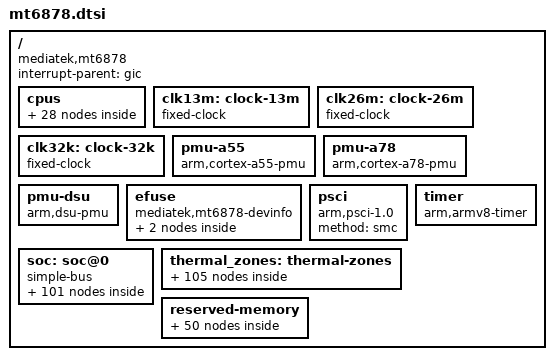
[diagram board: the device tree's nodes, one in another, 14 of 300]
// SPDX-License-Identifier: GPL-2.0 OR BSD-3-Clause
/*
 * MediaTek MT6878 SoC device tree source
 *
 * Copyright (c) 2025, Igor Belwon <igor.belwon@mentallysanemainliners.org>
 */

#include <dt-bindings/clock/mediatek,mt6878-clock.h>
#include <dt-bindings/interrupt-controller/arm-gic.h>
#include <dt-bindings/interrupt-controller/irq.h>
#include <dt-bindings/phy/phy.h>
#include <dt-bindings/power/mediatek,mt6878-power.h>
#include <dt-bindings/reset/ti-syscon.h>
#include <dt-bindings/thermal/mediatek,lvts-thermal.h>
#include <dt-bindings/thermal/thermal.h>
#include "mt6878-pinfunc.h"

/ {
	compatible = "mediatek,mt6878";
	#address-cells = <2>;
	#size-cells = <1>;

	interrupt-parent = <&gic>;

	cpus {
		#address-cells = <1>;
		#size-cells = <0>;

		cpu-map {
			cluster0 {
				core0 {
					cpu = <&cpu0>;
				};
				core1 {
					cpu = <&cpu1>;
				};
				core2 {
					cpu = <&cpu2>;
				};
				core3 {
					cpu = <&cpu3>;
				};
			};

			cluster1 {
				core0 {
					cpu = <&cpu4>;
				};
				core1 {
					cpu = <&cpu5>;
				};
				core2 {
					cpu = <&cpu6>;
				};
				core3 {
					cpu = <&cpu7>;
				};
			};
		};

		cpu0: cpu@0 {
			device_type = "cpu";
			compatible = "arm,cortex-a55";
			reg = <0x0>;
			performance-domains = <&performance 0>;
			enable-method = "psci";
			cpu-idle-states = <&cpuoff_l &clusteroff_l &mcusysoff_l
						&system_vcore &s2idle>;
			capacity-dmips-mhz  = <267>;
			#cooling-cells = <2>;
		};

		cpu1: cpu@1 {
			device_type = "cpu";
			compatible = "arm,cortex-a55";
			reg = <0x100>;
			performance-domains = <&performance 0>;
			enable-method = "psci";
			cpu-idle-states = <&cpuoff_l &clusteroff_l &mcusysoff_l
						&system_vcore &s2idle>;
			capacity-dmips-mhz  = <267>;
			#cooling-cells = <2>;
		};

		cpu2: cpu@2 {
			device_type = "cpu";
			compatible = "arm,cortex-a55";
			reg = <0x200>;
			performance-domains = <&performance 0>;
			enable-method = "psci";
			cpu-idle-states = <&cpuoff_l &clusteroff_l &mcusysoff_l
						&system_vcore &s2idle>;
			capacity-dmips-mhz  = <267>;
			#cooling-cells = <2>;
		};

		cpu3: cpu@3 {
			device_type = "cpu";
			compatible = "arm,cortex-a55";
			reg = <0x300>;
			performance-domains = <&performance 0>;
			enable-method = "psci";
			cpu-idle-states = <&cpuoff_l &clusteroff_l &mcusysoff_l
						&system_vcore &s2idle>;
			capacity-dmips-mhz  = <267>;
			#cooling-cells = <2>;
		};

		cpu4: cpu@100 {
			device_type = "cpu";
			compatible = "arm,cortex-a78";
			reg = <0x400>;
			performance-domains = <&performance 1>;
			enable-method = "psci";
			cpu-idle-states = <&cpuoff_b &clusteroff_b &mcusysoff_b
						&system_vcore &s2idle>;
			capacity-dmips-mhz  = <1024>;
			#cooling-cells = <2>;
		};

		cpu5: cpu@101 {
			device_type = "cpu";
			compatible = "arm,cortex-a78";
			reg = <0x500>;
			performance-domains = <&performance 1>;
			enable-method = "psci";
			cpu-idle-states = <&cpuoff_b &clusteroff_b &mcusysoff_b
						&system_vcore &s2idle>;
			capacity-dmips-mhz  = <1024>;
			#cooling-cells = <2>;
		};

		cpu6: cpu@102 {
			device_type = "cpu";
			compatible = "arm,cortex-a78";
			reg = <0x600>;
			performance-domains = <&performance 1>;
			enable-method = "psci";
			cpu-idle-states = <&cpuoff_b &clusteroff_b &mcusysoff_b
						&system_vcore &s2idle>;
			capacity-dmips-mhz  = <1024>;
			#cooling-cells = <2>;
		};

		cpu7: cpu@103 {
			device_type = "cpu";
			compatible = "arm,cortex-a78";
			reg = <0x700>;
			performance-domains = <&performance 1>;
			enable-method = "psci";
			cpu-idle-states = <&cpuoff_b &clusteroff_b &mcusysoff_b
						&system_vcore &s2idle>;
			capacity-dmips-mhz  = <1024>;
			#cooling-cells = <2>;
		};

		idle-states {
			entry-method = "arm,psci";

			cpuoff_l: cpuoff-l {
				compatible = "arm,idle-state";
				arm,psci-suspend-param = <0x00010000>;
				local-timer-stop;
				entry-latency-us = <25>;
				exit-latency-us = <57>;
				min-residency-us = <5700>;
			};

			cpuoff_b: cpuoff-b {
				compatible = "arm,idle-state";
				arm,psci-suspend-param = <0x00010000>;
				local-timer-stop;
				entry-latency-us = <35>;
				exit-latency-us = <82>;
				min-residency-us = <1890>;
			};

			clusteroff_l: clusteroff-l {
				compatible = "arm,idle-state";
				arm,psci-suspend-param = <0x01010001>;
				local-timer-stop;
				entry-latency-us = <57>;
				exit-latency-us = <134>;
				min-residency-us = <5700>;
			};

			clusteroff_b: clusteroff-b {
				compatible = "arm,idle-state";
				arm,psci-suspend-param = <0x01010001>;
				local-timer-stop;
				entry-latency-us = <50>;
				exit-latency-us = <144>;
				min-residency-us = <2460>;
			};

			mcusysoff_l: mcusysoff-l {
				compatible = "arm,idle-state";
				arm,psci-suspend-param = <0x02010007>;
				local-timer-stop;
				entry-latency-us = <863>;
				exit-latency-us = <1237>;
				min-residency-us = <5700>;
			};

			mcusysoff_b: mcusysoff-b {
				compatible = "arm,idle-state";
				arm,psci-suspend-param = <0x02010007>;
				local-timer-stop;
				entry-latency-us = <648>;
				exit-latency-us = <1172>;
				min-residency-us = <4570>;
			};

			system_vcore: system-vcore {
				compatible = "arm,idle-state";
				arm,psci-suspend-param = <0x020100ff>;
				local-timer-stop;
				entry-latency-us = <2400>;
				exit-latency-us = <4800>;
				min-residency-us = <35200>;
			};

			s2idle: s2idle {
				compatible = "arm,idle-state";
				arm,psci-suspend-param = <0x020180ff>;
				local-timer-stop;
				entry-latency-us = <10000>;
				exit-latency-us = <10000>;
				min-residency-us = <4294967295>;
			};
		};
	};

	clk13m: clock-13m {
		compatible = "fixed-clock";
		#clock-cells = <0>;
		clock-frequency = <13000000>;
		clock-output-names = "clk13m";
	};

	clk26m: clock-26m {
		compatible = "fixed-clock";
		#clock-cells = <0>;
		clock-frequency = <26000000>;
		clock-output-names = "clk26m";
	};

	clk32k: clock-32k {
		compatible = "fixed-clock";
		#clock-cells = <0>;
		clock-frequency = <32000>;
		clock-output-names = "clk32k";
	};

	pmu-a55 {
		compatible = "arm,cortex-a55-pmu";
		interrupt-parent = <&gic>;
		interrupts = <GIC_PPI 7 IRQ_TYPE_LEVEL_HIGH &ppi_cluster0>;
	};

	pmu-a78 {
		compatible = "arm,cortex-a78-pmu";
		interrupt-parent = <&gic>;
		interrupts = <GIC_PPI 7 IRQ_TYPE_LEVEL_HIGH &ppi_cluster1>;
	};

	pmu-dsu {
		compatible = "arm,dsu-pmu";
		cpus = <&cpu0>, <&cpu1>, <&cpu2>, <&cpu3>,
		       <&cpu4>, <&cpu5>, <&cpu6>, <&cpu7>;
		interrupts = <GIC_SPI 35 IRQ_TYPE_LEVEL_HIGH 0>;
	};

	/* efuse copy that LK passes in /chosen "atag,devinfo" */
	efuse: efuse {
		compatible = "mediatek,mt6878-devinfo";
		#address-cells = <1>;
		#size-cells = <1>;

		lvts_efuse_data1: lvts-data1@1ac {
			reg = <0x1ac 0x30>;
		};

		lvts_efuse_data2: lvts-data2@140 {
			reg = <0x140 0x14>;
		};
	};

	psci {
		compatible = "arm,psci-1.0";
		method = "smc";
	};

	soc: soc@0 {
		compatible = "simple-bus";
		ranges = <0x0 0x0 0x0 0x20000000>;

		#address-cells = <1>;
		#size-cells = <1>;

		/*
		 * CPU DVFS by the MCUPM firmware that the boot loader starts:
		 * the LUTs (frequencies, EM power) live in its CSRAM, the
		 * voltages are its business. 0x11c0cc: perf state in kHz flag.
		 */
		performance: performance-controller@11bc00 {
			compatible = "mediatek,mt6878-cpufreq-hw";
			reg = <0x0011bc10 0x120>,
			      <0x0011bd30 0x120>,
			      <0x0011c0cc 0x4>;
			#performance-domain-cells = <1>;
		};

		gic: interrupt-controller@c000000 {
			compatible = "arm,gic-v3";
			reg = <0x0c000000 0x40000>,
			      <0x0c040000 0x200000>;

			#interrupt-cells = <4>;
			interrupt-controller;
			interrupts = <GIC_PPI 9 IRQ_TYPE_LEVEL_HIGH 0>;

			ppi-partitions {
				ppi_cluster0: interrupt-partition-0 {
					affinity = <&cpu0 &cpu1 &cpu2 &cpu3>;
				};
				ppi_cluster1: interrupt-partition-1 {
					affinity = <&cpu4 &cpu5 &cpu6 &cpu7>;
				};
			};
		};

		/*
		 * Modem (CCCI). The node name is fixed: the stock LK looks
		 * up "/soc/mddriver" and writes "ccci,modem_info_v2" (where
		 * it left the modem arguments) into it; if LK did not start
		 * the modem it also sets status = "disabled".
		 *
		 * The MD power domain is not described on purpose (see
		 * scpsys): nothing may switch the modem until its driver
		 * owns the whole power sequence.
		 */
		modem: mddriver@d180000 {
			compatible = "mediatek,mt6878-ccci";
			reg = <0x0d180000 0x2000>,
			      <0x10209000 0x1000>,
			      <0x1020a000 0x1000>;
			reg-names = "md", "ccif-ap", "ccif-md";
			interrupts = <GIC_SPI 491 IRQ_TYPE_LEVEL_HIGH 0>,
				     <GIC_SPI 228 IRQ_TYPE_LEVEL_HIGH 0>,
				     <GIC_SPI 229 IRQ_TYPE_LEVEL_HIGH 0>;
			interrupt-names = "wdt", "ccif0", "ccif1";
			clocks = <&infracfg_ao CLK_IFRAO_CCIF_AP>,
				 <&infracfg_ao CLK_IFRAO_CCIF_MD>,
				 <&infracfg_ao CLK_IFRAO_CCIF1_AP>,
				 <&infracfg_ao CLK_IFRAO_CCIF1_MD>,
				 <&infracfg_ao CLK_IFRAO_CCIF4_MD>,
				 <&infracfg_ao CLK_IFRAO_CCIF5_MD>;
			clock-names = "ccif-ap", "ccif-md", "ccif1-ap",
				      "ccif1-md", "ccif4-md", "ccif5-md";
			mediatek,ccif-sram-size = <0x200>;
			status = "disabled";
		};

		topckgen: syscon@10000000 {
			compatible = "mediatek,mt6878-topckgen", "syscon";
			reg = <0x10000000 0x1000>;
			#clock-cells = <1>;

			hw-voter-regmap = <&hwv>;
		};

		infracfg_ao: clock-controller@10001000 {
			compatible = "mediatek,mt6878-infracfg-ao", "syscon";
			reg = <0x10001000 0x1000>;
			#clock-cells = <1>;
		};

		pio: pinctrl {
			compatible = "mediatek,mt6878-pinctrl";
			reg = <0x10005000 0x1000>,
			      <0x11d10000 0x1000>,
			      <0x11d30000 0x1000>,
			      <0x11d40000 0x1000>,
			      <0x11d50000 0x1000>,
			      <0x11d60000 0x1000>,
			      <0x11e20000 0x1000>,
			      <0x11e30000 0x1000>,
			      <0x11eb0000 0x1000>,
			      <0x11ec0000 0x1000>,
			      <0x11ce0000 0x1000>,
			      <0x11de0000 0x1000>,
			      <0x11e60000 0x1000>,
			      <0x1c01e000 0x1000>,
			      <0x11ce0000 0x1000>,
			      <0x11de0000 0x1000>,
			      <0x11e60000 0x1000>,
			      <0x1c01e000 0x1000>;
			reg-names = "gpio",
				    "iocfg_bl",
				    "iocfg_bm",
				    "iocfg_br",
				    "iocfg_bl1",
				    "iocfg_br1",
				    "iocfg_lm",
				    "iocfg_lt",
				    "iocfg_rm",
				    "iocfg_rt",
				    "eint-e",
				    "eint-s",
				    "eint-w",
				    "eint-c";
			gpio-controller;
			#gpio-cells = <2>;
			gpio-ranges = <&pio 0 0 196>;
			interrupt-controller;
			#interrupt-cells = <2>;
			interrupts = <GIC_SPI 239 IRQ_TYPE_LEVEL_HIGH 0>;
		};

		apmixedsys: syscon@1000c000 {
			compatible = "mediatek,mt6878-apmixedsys", "syscon";
			reg = <0x1000c000 0x1000>;
			#clock-cells = <1>;

			mediatek,hardware-voter = <&hwv>;
		};

		nemicfg_ao: syscon@10270000 {
			compatible = "mediatek,mt6878-nemicfg-ao", "syscon";
			reg = <0x10270000 0x1000>;
		};

		/*
		 * LVTS: set up by the boot firmware (calibration, sensing
		 * points, hardware thermal reset at 119 C), only read here.
		 * The interrupts (GIC_SPI 218/219) are not used, the zones
		 * are polled; the GPU domain (0x13ff0000) is not started by
		 * the firmware and is not described.
		 */
		lvts_ap: thermal-sensor@10315000 {
			compatible = "mediatek,mt6878-lvts-ap";
			reg = <0x10315000 0x1000>;
			nvmem-cells = <&lvts_efuse_data1>, <&lvts_efuse_data2>;
			nvmem-cell-names = "lvts-calib-data-1", "lvts-calib-data-2";
			#thermal-sensor-cells = <1>;
			status = "disabled";
		};

		lvts_mcu: thermal-sensor@10316000 {
			compatible = "mediatek,mt6878-lvts-mcu";
			reg = <0x10316000 0x1000>;
			nvmem-cells = <&lvts_efuse_data1>, <&lvts_efuse_data2>;
			nvmem-cell-names = "lvts-calib-data-1", "lvts-calib-data-2";
			#thermal-sensor-cells = <1>;
			status = "disabled";
		};

		hwv: syscon@10320000 {
			compatible = "mediatek,mt6878-hwv", "syscon";
			reg = <0x10320000 0x2000>;
		};

		uart0: serial@11001000 {
			compatible = "mediatek,mt6577-uart";
			reg = <0x11001000 0x1000>;
			interrupts = <GIC_SPI 397 IRQ_TYPE_LEVEL_HIGH 0>;
			clocks = <&clk26m>, <&pericfg_ao CLK_PERAOP_UART0>;
			clock-names = "baud", "bus";
			status = "disabled";
		};

		uart1: serial@11002000 {
			compatible = "mediatek,mt6577-uart";
			reg = <0x11002000 0x1000>;
			interrupts = <GIC_SPI 398 IRQ_TYPE_LEVEL_HIGH 0>;
			clocks = <&clk26m>, <&pericfg_ao CLK_PERAOP_UART1>;
			clock-names = "baud", "bus";
			status = "disabled";
		};

		uart2: serial@11003000 {
			compatible = "mediatek,mt6577-uart";
			reg = <0x11003000 0x1000>;
			interrupts = <GIC_SPI 399 IRQ_TYPE_LEVEL_HIGH 0>;
			clocks = <&clk26m>, <&pericfg_ao CLK_PERAOP_UART2>;
			clock-names = "baud", "bus";
			status = "disabled";
		};

		disp_pwm0: pwm@1100e000 {
			compatible = "mediatek,mt6878-disp-pwm";
			reg = <0x1100e000 0x1000>;
			interrupts = <GIC_SPI 254 IRQ_TYPE_LEVEL_HIGH 0>;
			#pwm-cells = <2>;
			clocks = <&pericfg_ao CLK_PERAOP_DISP_PWM0>,
				 <&topckgen CLK_TOP_DISP_PWM_SEL>;
			clock-names = "main", "mm";
			status = "disabled";
		};

		disp_pwm1: pwm@1100f000 {
			compatible = "mediatek,mt6878-disp-pwm";
			reg = <0x1100f000 0x1000>;
			interrupts = <GIC_SPI 254 IRQ_TYPE_LEVEL_HIGH 0>;
			#pwm-cells = <2>;
			clocks = <&pericfg_ao CLK_PERAOP_DISP_PWM1>,
				 <&topckgen CLK_TOP_DISP_PWM_SEL>;
			clock-names = "main", "mm";
			status = "disabled";
		};

		pericfg_ao: syscon@11036000 {
			compatible = "mediatek,mt6878-pericfg-ao", "syscon";
			reg = <0x11036000 0x1000>;
			#clock-cells = <1>;
		};

		afe: audio-controller@11050000 {
			compatible = "mediatek,mt6878-afe";
			reg = <0x11050000 0x9000>;
			interrupts = <GIC_SPI 392 IRQ_TYPE_LEVEL_HIGH 0>;
			power-domains = <&spm MT6878_POWER_DOMAIN_AUDIO>;
			clocks = <&topckgen CLK_TOP_AUD_INTBUS_SEL>,
				 <&topckgen CLK_TOP_AUD_1_SEL>,
				 <&topckgen CLK_TOP_AUD_2_SEL>,
				 <&topckgen CLK_TOP_AUD_ENGEN1_SEL>,
				 <&topckgen CLK_TOP_AUD_ENGEN2_SEL>,
				 <&topckgen CLK_TOP_AUDIO_H_SEL>,
				 <&topckgen CLK_TOP_APLL1>,
				 <&topckgen CLK_TOP_APLL2>,
				 <&topckgen CLK_TOP_APLL1_D4>,
				 <&topckgen CLK_TOP_APLL2_D4>,
				 <&topckgen CLK_TOP_TCK_26M_MX9>,
				 <&pericfg_ao CLK_PERAOP_AUDIO0>,
				 <&pericfg_ao CLK_PERAOP_AUDIO1>,
				 <&pericfg_ao CLK_PERAOP_AUDIO2>;
			clock-names = "top_aud_intbus",
				      "top_aud_1",
				      "top_aud_2",
				      "top_aud_eng1",
				      "top_aud_eng2",
				      "top_aud_h",
				      "apll1",
				      "apll2",
				      "apll1_d4",
				      "apll2_d4",
				      "clk26m",
				      "peri_aud_slv",
				      "peri_aud_mst",
				      "peri_aud_intbus";
			status = "disabled";
		};

		ssusb: usb0@11201000 {
			compatible = "mediatek,mtu3";
			reg = <0x11201000 0x2e00>,
			      <0x11203e00 0x100>;
			reg-names = "mac", "ippc";
			interrupts = <GIC_SPI 384 IRQ_TYPE_LEVEL_HIGH 0>;
			phy-cells = <1>;
			phys = <&u2port PHY_TYPE_USB2>;
			clocks = <&topckgen CLK_TOP_USB_TOP_SEL>,
				 <&topckgen CLK_TOP_USB_XHCI_SEL>,
				 <&pericfg_ao CLK_PERAOP_SSUSB0_FRMCNT>;
			clock-names = "sys_ck", "host_ck", "frmcnt_ck";
			#address-cells = <1>;
			#size-cells = <1>;
			ranges;
			mediatek,syscon-wakeup = <&pericfg_ao 0x214 105>;
			wakeup-source;
			status = "disabled";

			usb_host: xhci0@11200000 {
				compatible = "mediatek,mtk-xhci";
				reg = <0x11200000 0x1000>;
				reg-names = "mac";
				interrupts = <GIC_SPI 385 IRQ_TYPE_LEVEL_HIGH 0>;
				clocks = <&clk26m>;
				clock-names = "sys_ck";

				port {
					usb_role: endpoint {
						remote-endpoint = <&mtu3_drd_switch>;
					};
				};
			};
		};

		ufsphy: ufsphy@112a0000 {
			compatible = "mediatek,mt8183-ufsphy";
			#phy-cells = <0>;
			clocks = <&clk26m>, <&clk26m>;
			clock-names = "unipro", "mp";
			reg = <0x112a0000 0x10000>;
			status = "disabled";
		};

		ufshci: ufshci@112b0000 {
			compatible = "mediatek,mt8183-ufshci";
			reg = <0x112b0000 0x2300>;
			phys = <&ufsphy>;
			interrupts = <GIC_SPI 393 IRQ_TYPE_LEVEL_HIGH 0>;

			clocks =
				<&topckgen CLK_TOP_UFS_SEL>,
				<&topckgen CLK_TOP_AES_UFSFDE_SEL>,
				<&topckgen CLK_TOP_UFS_MBIST_SEL>,
				<&ufscfg_ao CLK_UFSAO_UNIPRO_TX_SYM>,
				<&ufscfg_ao CLK_UFSAO_UNIPRO_RX_SYM0>,
				<&ufscfg_ao CLK_UFSAO_UNIPRO_RX_SYM1>,
				<&ufscfg_ao CLK_UFSAO_UNIPRO_SYS>,
				<&ufscfg_ao CLK_UFSAO_UNIPRO_SAP_CFG>,
				<&ufscfg_ao CLK_UFSAO_PHY_TOP_AHB_S_BUS>,
				<&ufscfg_pdn CLK_UFSPDN_UFSHCI>,
				<&ufscfg_pdn CLK_UFSPDN_UFSHCI_AES>,
				<&ufscfg_pdn CLK_UFSPDN_UFSHCI_AHB>,
				<&ufscfg_pdn CLK_UFSPDN_UFSHCI_AXI>;

			clock-names =
				"ufs_sel",
				"ufs_fde",
				"ufs_mbist",
				"unipro_tx_sym",
				"unipro_rx_sym0",
				"unipro_rx_sym1",
				"unipro_sys",
				"unipro_phy_sap",
				"phy_top_ahb_s_bus",
				"ufshci_ufs",
				"ufshci_aes",
				"ufshci_ufs_ahb",
				"ufshci_aes_axi";

			freq-table-hz =
				<0 0>,
				<0 0>,
				<0 0>,
				<0 0>,
				<0 0>,
				<0 0>,
				<0 0>,
				<0 0>,
				<0 0>,
				<0 0>,
				<0 0>,
				<0 0>,
				<0 0>;

			resets =	<&ufscfgpdn_rst 0>,
					<&ufscfgpdn_rst 1>,
					<&ufscfgpdn_rst 2>;
			reset-names =	"unipro_rst",
					"crypto_rst",
					"hci_rst";

			mediatek,ufs-disable-mcq;
			status = "disabled";
		};

		ufscfg_ao: syscon@112b8000 {
			compatible = "mediatek,mt6878-ufscfg-ao", "syscon", "simple-mfd";
			reg = <0x112b8000 0x1000>;
			#clock-cells = <1>;

			ufscfgao_rst: reset-controller {
				compatible = "ti,syscon-reset";
				#reset-cells = <1>;

				ti,reset-bits = <
					0x48 8 0x4c 8 0 0 (ASSERT_SET | DEASSERT_SET | STATUS_NONE)
				>;
			};
		};

		ufscfg_pdn: syscon@112bb000 {
			compatible = "mediatek,mt6878-ufscfg-pdn", "syscon", "simple-mfd";
			reg = <0x112bb000 0x1000>;
			#clock-cells = <1>;

			ufscfgpdn_rst: reset-controller {
				compatible = "ti,syscon-reset";
				#reset-cells = <1>;

				ti,reset-bits = <
					0x48 0 0x4c 0 0 0 (ASSERT_SET | DEASSERT_SET | STATUS_NONE)
					0x48 1 0x4c 1 0 0 (ASSERT_SET | DEASSERT_SET | STATUS_NONE)
					0x48 2 0x4c 2 0 0 (ASSERT_SET | DEASSERT_SET | STATUS_NONE)
				>;
			};
		};

		imp_iic_wrap_cs: syscon@11281000 {
			compatible = "mediatek,mt6878-imp_iic_wrap-cs", "syscon";
			reg = <0x11281000 0x1000>;
			#clock-cells = <1>;
		};

		i2c0: i2c@11c20000 {
			compatible = "mediatek,mt6878-i2c",
				     "mediatek,mt8188-i2c";
			reg = <0x11c20000 0x1000>,
			      <0x11300200 0x80>;
			interrupts = <GIC_SPI 400 IRQ_TYPE_LEVEL_HIGH 0>;
			clocks = <&imp_iic_wrap_es CLK_IMP_E_S_I3C0_W1S>,
				<&pericfg_ao CLK_PERAOP_DMA_B>;
			clock-names = "main", "dma";
			clock-div = <1>;
		};

		i2c1: i2c@11c21000 {
			compatible = "mediatek,mt6878-i2c",
				     "mediatek,mt8188-i2c";
			reg = <0x11c21000 0x1000>,
			      <0x11300280 0x80>;
			interrupts = <GIC_SPI 401 IRQ_TYPE_LEVEL_HIGH 0>;
			clocks = <&imp_iic_wrap_es CLK_IMP_E_S_I3C1_W1S>,
				<&pericfg_ao CLK_PERAOP_DMA_B>;
			clock-names = "main", "dma";
			clock-div = <1>;
		};

		i2c2: i2c@11c22000 {
			compatible = "mediatek,mt6878-i2c",
				     "mediatek,mt8188-i2c";
			reg = <0x11c22000 0x1000>,
			      <0x11300300 0x100>;
			interrupts = <GIC_SPI 402 IRQ_TYPE_LEVEL_HIGH 0>;
			clocks = <&imp_iic_wrap_es CLK_IMP_E_S_I3C2_W1S>,
				<&pericfg_ao CLK_PERAOP_DMA_B>;
			clock-names = "main", "dma";
			clock-div = <1>;
		};

		imp_iic_wrap_es: syscon@11c25000 {
			compatible = "mediatek,mt6878-imp_iic_wrap-es", "syscon";
			reg = <0x11c25000 0x1000>;
			#clock-cells = <1>;
		};

		i2c3: i2c@11e00000 {
			compatible = "mediatek,mt6878-i2c",
				     "mediatek,mt8188-i2c";
			reg = <0x11e00000 0x1000>,
			      <0x11300400 0x80>;
			interrupts = <GIC_SPI 403 IRQ_TYPE_LEVEL_HIGH 0>;
			clocks = <&imp_iic_wrap_ws CLK_IMP_W_S_I3C3_W1S>,
				<&pericfg_ao CLK_PERAOP_DMA_B>;
			clock-names = "main", "dma";
			clock-div = <1>;
		};

		i2c4: i2c@11c23000 {
			compatible = "mediatek,mt6878-i2c",
				     "mediatek,mt8188-i2c";
			reg = <0x11c23000 0x1000>,
			      <0x11300480 0x100>;
			interrupts = <GIC_SPI 404 IRQ_TYPE_LEVEL_HIGH 0>;
			clocks = <&imp_iic_wrap_es CLK_IMP_E_S_I3C4_W1S>,
				<&pericfg_ao CLK_PERAOP_DMA_B>;
			clock-names = "main", "dma";
			clock-div = <1>;
		};

		i2c5: i2c@11280000 {
			compatible = "mediatek,mt6878-i2c",
				     "mediatek,mt8188-i2c";
			#address-cells = <1>;
			#size-cells = <0>;
			reg = <0x11280000 0x1000>,
			      <0x11300580 0x80>;
			interrupts = <GIC_SPI 405 IRQ_TYPE_LEVEL_HIGH 0>;
			clocks = <&imp_iic_wrap_cs CLK_IM_C_S_I3C5_W1S>,
				<&pericfg_ao CLK_PERAOP_DMA_B>;
			clock-names = "main", "dma";
			clock-div = <1>;
		};

		i2c6: i2c@11e01000 {
			compatible = "mediatek,mt6878-i2c",
				     "mediatek,mt8188-i2c";
			#address-cells = <1>;
			#size-cells = <0>;
			reg = <0x11e01000 0x1000>,
			      <0x11300600 0x80>;
			interrupts = <GIC_SPI 406 IRQ_TYPE_LEVEL_HIGH 0>;
			clocks = <&imp_iic_wrap_ws CLK_IMP_W_S_I3C6_W1S>,
				<&pericfg_ao CLK_PERAOP_DMA_B>;
			clock-names = "main", "dma";
			clock-div = <1>;
		};

		i2c7: i2c@11e02000 {
			compatible = "mediatek,mt6878-i2c",
				     "mediatek,mt8188-i2c";
			reg = <0x11e02000 0x1000>,
			      <0x11300680 0x100>;
			interrupts = <GIC_SPI 407 IRQ_TYPE_LEVEL_HIGH 0>;
			clocks = <&imp_iic_wrap_ws CLK_IMP_W_S_I3C7_W1S>,
				<&pericfg_ao CLK_PERAOP_DMA_B>;
			clock-names = "main", "dma";
			clock-div = <1>;
			scl-gpio-id = <139>;
			sda-gpio-id = <140>;
		};

		i2c8: i2c@11e03000 {
			compatible = "mediatek,mt6878-i2c",
				     "mediatek,mt8188-i2c";
			reg = <0x11e03000 0x1000>,
			      <0x11300780 0x100>;
			interrupts = <GIC_SPI 408 IRQ_TYPE_LEVEL_HIGH 0>;
			clocks = <&imp_iic_wrap_ws CLK_IMP_W_S_I3C8_W1S>,
				<&pericfg_ao CLK_PERAOP_DMA_B>;
			clock-names = "main", "dma";
			clock-div = <1>;
		};

		imp_iic_wrap_ws: syscon@11e04000 {
			compatible = "mediatek,mt6878-imp_iic_wrap-ws", "syscon";
			reg = <0x11e04000 0x1000>;
			#clock-cells = <1>;
		};

		i2c9: i2c@11c24000 {
			compatible = "mediatek,mt6878-i2c",
				     "mediatek,mt8188-i2c";
			reg = <0x11c24000 0x1000>,
			      <0x11300880 0x100>;
			interrupts = <GIC_SPI 409 IRQ_TYPE_LEVEL_HIGH 0>;
			clocks = <&imp_iic_wrap_es CLK_IMP_E_S_I3C9_W1S>,
				<&pericfg_ao CLK_PERAOP_DMA_B>;
			clock-names = "main", "dma";
			clock-div = <1>;
		};

		i2c10: i2c@11d70000 {
			compatible = "mediatek,mt6878-i2c",
				     "mediatek,mt8188-i2c";
			reg = <0x11d70000 0x1000>,
			      <0x11300980 0x80>;
			interrupts = <GIC_SPI 410 IRQ_TYPE_LEVEL_HIGH 0>;
			clocks = <&imp_iic_wrap_ess CLK_IMP_ES_S_I3C10_W1S>,
				<&pericfg_ao CLK_PERAOP_DMA_B>;
			clock-names = "main", "dma";
			clock-div = <1>;
		};

		i2c11: i2c@11d71000 {
			compatible = "mediatek,mt6878-i2c",
				     "mediatek,mt8188-i2c";
			reg = <0x11d71000 0x1000>,
			      <0x11300a00 0x80>;
			interrupts = <GIC_SPI 411 IRQ_TYPE_LEVEL_HIGH 0>;
			clocks = <&imp_iic_wrap_ess CLK_IMP_ES_S_I3C11_W1S>,
				<&pericfg_ao CLK_PERAOP_DMA_B>;
			clock-names = "main", "dma";
			clock-div = <1>;
		};

		i2c12: i2c@11d72000 {
			compatible = "mediatek,mt6878-i2c",
				     "mediatek,mt8188-i2c";
			reg = <0x11d72000 0x1000>,
			      <0x11300a80 0x80>;
			interrupts = <GIC_SPI 412 IRQ_TYPE_LEVEL_HIGH 0>;
			clocks = <&imp_iic_wrap_ess CLK_IMP_ES_S_I3C12_W1S>,
				<&pericfg_ao CLK_PERAOP_DMA_B>;
			clock-names = "main", "dma";
			clock-div = <1>;
		};

		imp_iic_wrap_ess: syscon@11d73000 {
			compatible = "mediatek,mt6878-imp_iic_wrap-ess", "syscon";
			reg = <0x11d73000 0x1000>;
			#clock-cells = <1>;
		};

		/*
		 * D-PHY of DSI0. Placeholder: mainline has no driver for this
		 * PHY generation yet (register layout differs from mt8183).
		 */
		mipi_tx0: dsi-phy@11e50000 {
			compatible = "mediatek,mt6878-mipi-tx";
			reg = <0x11e50000 0x1000>;
			clocks = <&clk26m>;
			#clock-cells = <0>;
			#phy-cells = <0>;
			clock-output-names = "mipi_tx0_pll";
			status = "disabled";
		};

		usbphy: t-phy@11f40000 {
			compatible = "mediatek,mt6785-tphy", "mediatek,generic-tphy-v2";
			#address-cells = <1>;
			#size-cells = <1>;
			ranges = <0x0 0x11f40000 0x1000>;
			status = "disabled";

			u2port: usb-phy@0 {
				reg = <0x0 0x700>;
				clocks = <&clk26m>;
				clock-names = "ref";
				#phy-cells = <1>;
				mediatek,software-role-switch;
				status = "disabled";

				port {
					mtu3_drd_switch: endpoint {
						remote-endpoint = <&usb_role>;
					};
				};
			};
		};

		/*
		 * Mali-G615 MC2. Powered and clocked through the GPUEB
		 * (gpufreq below); needs arm/mali/arch11.8/mali_csffw.bin.
		 */
		gpu: gpu@13000000 {
			compatible = "mediatek,mt6878-mali", "arm,mali-valhall-csf";
			reg = <0x13000000 0x480000>;
			interrupts = <GIC_SPI 271 IRQ_TYPE_LEVEL_HIGH 0>,
				     <GIC_SPI 270 IRQ_TYPE_LEVEL_HIGH 0>,
				     <GIC_SPI 269 IRQ_TYPE_LEVEL_HIGH 0>;
			interrupt-names = "job", "mmu", "gpu";
			clocks = <&gpufreq 0>, <&gpufreq 1>;
			clock-names = "core", "stacks";
			power-domains = <&gpufreq>;
			#cooling-cells = <2>;
			status = "disabled";
		};

		/*
		 * GPUEB, the GPU power and frequency MCU. The boot firmware
		 * loads and starts it in MFG0; it owns the GPU supplies, PLLs
		 * and MFG1+ power domains. Its shared memory is the LK-made
		 * "mediatek,me_GPUEB_SHARED" carveout.
		 */
		gpufreq: power-controller@13c3fd1c {
			compatible = "mediatek,mt6878-gpufreq";
			reg = <0x13c3fd1c 0x64>;
			reg-names = "gpr";
			mboxes = <&gpueb_mbox 1>;
			mbox-names = "gpufreq";
			mediatek,scpsys = <&scpsys>;
			#clock-cells = <1>;
			#nvmem-cell-cells = <0>;
			#power-domain-cells = <0>;
			status = "disabled";
		};

		gpueb_mbox: mailbox@13c3fd80 {
			compatible = "mediatek,mt6878-gpueb-mbox";
			reg = <0x13c3fd80 0x280>,
			      <0x13c62000 0x7c>;
			reg-names = "data", "ctl";
			interrupts = <GIC_SPI 273 IRQ_TYPE_LEVEL_HIGH 0>;
			#mbox-cells = <1>;
			status = "disabled";
		};

		/*
		 * The GPU PLL controllers sit in the MFG block, which the GPU
		 * microcontroller (GPUEB) powers on and off on its own. Reading
		 * them while MFG is down stalls the bus, so keep them disabled
		 * until there is a GPU driver that holds MFG up.
		 */
		mfgpll: clock-controller@13fa0000 {
			compatible = "mediatek,mt6878-mfgpll-pll-ctrl", "syscon";
			reg = <0x13fa0000 0x800>;
			#clock-cells = <1>;
			status = "disabled";
		};

		mfgscpll: clock-controller@13fa0c00 {
			compatible = "mediatek,mt6878-mfgscpll-pll-ctrl", "syscon";
			reg = <0x13fa0c00 0x1000>;
			#clock-cells = <1>;
			status = "disabled";
		};

		/*
		 * The multimedia clock controllers below sit in switchable
		 * power domains; they stay disabled until the nodes get their
		 * power-domains from the SPM power controller.
		 */
		mmsys: syscon@14000000 {
			compatible = "mediatek,mt6878-mmsys", "syscon";
			reg = <0x14000000 0x1000>;
			#clock-cells = <1>;
			status = "disabled";
		};

		/*
		 * Display pipeline (mediatek-drm). Only the blocks of the main
		 * path are described: OVL0_2L wired to DSI0 through the mmsys
		 * crossbars, with the picture quality engines bypassed. There is
		 * no IOMMU driver yet: the boot loader leaves the display larb
		 * ports in bypass, so OVL reads physical addresses.
		 */
		disp_mutex0: mutex@14001000 {
			compatible = "mediatek,mt6878-disp-mutex";
			reg = <0x14001000 0x1000>;
			interrupts = <GIC_SPI 303 IRQ_TYPE_LEVEL_HIGH 0>;
			clocks = <&mmsys CLK_MM_DISP_MUTEX0>;
			power-domains = <&spm MT6878_POWER_DOMAIN_DISP>;
			status = "disabled";
		};

		disp_ovl0_2l: ovl@14002000 {
			compatible = "mediatek,mt6878-disp-ovl-2l",
				     "mediatek,mt8192-disp-ovl-2l";
			reg = <0x14002000 0x1000>;
			interrupts = <GIC_SPI 302 IRQ_TYPE_LEVEL_HIGH 0>;
			clocks = <&mmsys CLK_MM_DISP_OVL0_2L>;
			power-domains = <&spm MT6878_POWER_DOMAIN_DISP>;
			status = "disabled";
		};

		dsi0: dsi@1401a000 {
			compatible = "mediatek,mt6878-dsi", "mediatek,mt8186-dsi";
			reg = <0x1401a000 0x1000>;
			interrupts = <GIC_SPI 328 IRQ_TYPE_LEVEL_HIGH 0>;
			clocks = <&mmsys CLK_MM_DISP_DSI0>,
				 <&mmsys CLK_MM_DSI0>,
				 <&mipi_tx0>;
			clock-names = "engine", "digital", "hs";
			phys = <&mipi_tx0>;
			phy-names = "dphy";
			power-domains = <&spm MT6878_POWER_DOMAIN_DISP>;
			#address-cells = <1>;
			#size-cells = <0>;
			status = "disabled";
		};

		imgsys: clock-controller@15000000 {
			compatible = "mediatek,mt6878-imgsys", "syscon";
			reg = <0x15000000 0x1000>;
			#clock-cells = <1>;
			status = "disabled";
		};

		imgsys1_dip_top: clock-controller@15110000 {
			compatible = "mediatek,mt6878-imgsys1-dip-top", "syscon";
			reg = <0x15110000 0x1000>;
			#clock-cells = <1>;
			status = "disabled";
		};

		imgsys1_dip_nr1: clock-controller@15130000 {
			compatible = "mediatek,mt6878-imgsys1-dip-nr1", "syscon";
			reg = <0x15130000 0x1000>;
			#clock-cells = <1>;
			status = "disabled";
		};

		imgsys1_dip_nr2: clock-controller@15170000 {
			compatible = "mediatek,mt6878-imgsys1-dip-nr2", "syscon";
			reg = <0x15170000 0x1000>;
			#clock-cells = <1>;
			status = "disabled";
		};

		imgsys_wpe1: clock-controller@15220000 {
			compatible = "mediatek,mt6878-imgsys-wpe1", "syscon";
			reg = <0x15220000 0x1000>;
			#clock-cells = <1>;
			status = "disabled";
		};

		imgsys_wpe2: clock-controller@15520000 {
			compatible = "mediatek,mt6878-imgsys-wpe2", "syscon";
			reg = <0x15520000 0x1000>;
			#clock-cells = <1>;
			status = "disabled";
		};

		imgsys_traw: clock-controller@15710000 {
			compatible = "mediatek,mt6878-imgsys-traw", "syscon";
			reg = <0x15710000 0x1000>;
			#clock-cells = <1>;
			status = "disabled";
		};

		imgsys_vcore: clock-controller@15780000 {
			compatible = "mediatek,mt6878-imgsys-vcore", "syscon";
			reg = <0x15780000 0x1000>;
			#clock-cells = <1>;
			status = "disabled";
		};

		vdecsys: clock-controller@1602f000 {
			compatible = "mediatek,mt6878-vdecsys", "syscon";
			reg = <0x1602f000 0x1000>;
			#clock-cells = <1>;
			status = "disabled";
		};

		vencsys: clock-controller@17000000 {
			compatible = "mediatek,mt6878-vencsys", "syscon";
			reg = <0x17000000 0x1000>;
			#clock-cells = <1>;
			status = "disabled";
		};

		camsys_main: clock-controller@1a000000 {
			compatible = "mediatek,mt6878-camsys-main", "syscon";
			reg = <0x1a000000 0x1000>;
			#clock-cells = <1>;
			status = "disabled";
		};

		camsys_rawa: clock-controller@1a04f000 {
			compatible = "mediatek,mt6878-camsys-rawa", "syscon";
			reg = <0x1a04f000 0x1000>;
			#clock-cells = <1>;
			status = "disabled";
		};

		camsys_yuva: clock-controller@1a06f000 {
			compatible = "mediatek,mt6878-camsys-yuva", "syscon";
			reg = <0x1a06f000 0x1000>;
			#clock-cells = <1>;
			status = "disabled";
		};

		camsys_rawb: clock-controller@1a08f000 {
			compatible = "mediatek,mt6878-camsys-rawb", "syscon";
			reg = <0x1a08f000 0x1000>;
			#clock-cells = <1>;
			status = "disabled";
		};

		camsys_yuvb: clock-controller@1a0af000 {
			compatible = "mediatek,mt6878-camsys-yuvb", "syscon";
			reg = <0x1a0af000 0x1000>;
			#clock-cells = <1>;
			status = "disabled";
		};

		camsys_mraw: clock-controller@1a170000 {
			compatible = "mediatek,mt6878-camsys-mraw", "syscon";
			reg = <0x1a170000 0x1000>;
			#clock-cells = <1>;
			status = "disabled";
		};

		ccusys: clock-controller@1b200000 {
			compatible = "mediatek,mt6878-ccusys", "syscon";
			reg = <0x1b200000 0x1000>;
			#clock-cells = <1>;
			status = "disabled";
		};

		camsys_vcore: clock-controller@1b204000 {
			compatible = "mediatek,mt6878-camsys-vcore", "syscon";
			reg = <0x1b204000 0x1000>;
			#clock-cells = <1>;
			status = "disabled";
		};

		scpsys: syscon@1c001000 {
			compatible = "mediatek,mt6878-scpsys", "syscon", "simple-mfd";
			reg = <0x1c001000 0x1000>;

			/*
			 * Not described on purpose:
			 * - MD: owned by the modem; Linux must never switch it.
			 * - MFG0: switched by the GPU microcontroller (GPUEB).
			 * - APU: switched by the APU firmware.
			 * - CAM and ISP trees: need the camera/ISP vcore supply.
			 */
			spm: power-controller {
				compatible = "mediatek,mt6878-power-controller";
				#address-cells = <1>;
				#size-cells = <0>;
				#power-domain-cells = <1>;
				access-controllers = <&infracfg_ao>, <&vlpcfg>, <&nemicfg_ao>;
				mediatek,hardware-voter = <&hwv>;
				status = "disabled";

				power-domain@MT6878_POWER_DOMAIN_CONN {
					reg = <MT6878_POWER_DOMAIN_CONN>;
					#power-domain-cells = <0>;
				};

				power-domain@MT6878_POWER_DOMAIN_AUDIO {
					reg = <MT6878_POWER_DOMAIN_AUDIO>;
					clocks = <&topckgen CLK_TOP_AUD_INTBUS_SEL>;
					clock-names = "audio";
					#power-domain-cells = <0>;
				};

				power-domain@MT6878_POWER_DOMAIN_CSI_RX {
					reg = <MT6878_POWER_DOMAIN_CSI_RX>;
					#power-domain-cells = <0>;
				};

				power-domain@MT6878_POWER_DOMAIN_SSR {
					reg = <MT6878_POWER_DOMAIN_SSR>;
					#power-domain-cells = <0>;
				};

				power-domain@MT6878_POWER_DOMAIN_SSUSB {
					reg = <MT6878_POWER_DOMAIN_SSUSB>;
					#power-domain-cells = <0>;
				};

				power-domain@MT6878_POWER_DOMAIN_MM_INFRA {
					reg = <MT6878_POWER_DOMAIN_MM_INFRA>;
					clocks = <&topckgen CLK_TOP_MMINFRA_SEL>;
					clock-names = "mm_infra";
					#address-cells = <1>;
					#size-cells = <0>;
					#power-domain-cells = <1>;

					power-domain@MT6878_POWER_DOMAIN_DISP {
						reg = <MT6878_POWER_DOMAIN_DISP>;
						clocks = <&topckgen CLK_TOP_DISP0_SEL>;
						clock-names = "disp";
						#power-domain-cells = <0>;
					};

					power-domain@MT6878_POWER_DOMAIN_VEN0 {
						reg = <MT6878_POWER_DOMAIN_VEN0>;
						clocks = <&topckgen CLK_TOP_VENC_SEL>;
						clock-names = "ven";
						#power-domain-cells = <0>;
					};

					power-domain@MT6878_POWER_DOMAIN_VDE0 {
						reg = <MT6878_POWER_DOMAIN_VDE0>;
						clocks = <&topckgen CLK_TOP_VDEC_SEL>;
						clock-names = "vde";
						#power-domain-cells = <0>;
					};

					power-domain@MT6878_POWER_DOMAIN_MM_PROC_DORMANT {
						reg = <MT6878_POWER_DOMAIN_MM_PROC_DORMANT>;
						clocks = <&topckgen CLK_TOP_MMUP_SEL>;
						clock-names = "mmup";
						#power-domain-cells = <0>;
					};
				};
			};
		};

		vlpcfg: syscon@1c00c000 {
			compatible = "mediatek,mt6878-vlpcfg", "syscon";
			reg = <0x1c00c000 0x1000>;
		};

		watchdog: watchdog@1c00a000 {
			compatible = "mediatek,mt6878-wdt",
				     "mediatek,mt6589-wdt",
				     "syscon";
			reg = <0x1c00a000 0x100>;

			reboot-mode {
				compatible = "syscon-reboot-mode";
				offset = <0x24>;
				mask = <0xf>;
				mode-charger = <0x1>;
				mode-recovery = <0x2>;
				mode-bootloader = <0x3>;
				mode-dm-verity-dev-corrupt = <0x4>;
				mode-kpoc = <0x5>;
				mode-ddr-reserve = <0x6>;
				mode-meta = <0x7>;
				mode-rpmbpk = <0x8>;
			};
		};

		vlpckgen: clock-controller@1c012000 {
			compatible = "mediatek,mt6878-vlpckgen", "syscon";
			reg = <0x1c012000 0x1000>;
			#clock-cells = <1>;
		};

		/*
		 * Part of the SCP (sensor hub) subsystem: only accessible while
		 * the SCP is powered and clocked, which Linux does not control
		 * yet. Nothing uses these gates so far.
		 */
		scp_cfg: clock-controller@1cb21000 {
			compatible = "mediatek,mt6878-scp-cfg", "syscon";
			reg = <0x1cb21000 0x1000>;
			#clock-cells = <1>;
			status = "disabled";
		};

		spmi: spmi@1cc04000 {
			compatible = "mediatek,mt6878-spmi";
			reg = <0x1cc04000 0x900>,
			      <0x1cc01000 0x100>;
			reg-names = "pmif", "spmimst";
			interrupts-extended = <&pio 212 IRQ_TYPE_LEVEL_HIGH>;
			interrupt-names = "rcs";
			interrupt-controller;
			#interrupt-cells = <3>;
			#address-cells = <2>;
			#size-cells = <0>;
			status = "disabled";
		};

		/*
		 * Always-on system timer. Every idle state of the CPUs stops
		 * the arch timer, so this is the tick broadcast device that
		 * lets all of them, and with them MCUSYS, power down at once.
		 */
		systimer: timer@1cc10000 {
			compatible = "mediatek,mt6878-timer",
				     "mediatek,mt6765-timer";
			reg = <0x1cc10000 0x1000>;
			interrupts = <GIC_SPI 249 IRQ_TYPE_LEVEL_HIGH 0>;
			clocks = <&clk13m>;
			status = "disabled";
		};

		mminfra_config: clock-controller@1e800000 {
			compatible = "mediatek,mt6878-mminfra-config", "syscon";
			reg = <0x1e800000 0x1000>;
			#clock-cells = <1>;
			mediatek,hardware-voter = <&hwv>;
			status = "disabled";
		};

		mdpsys: clock-controller@1f000000 {
			compatible = "mediatek,mt6878-mdpsys", "syscon";
			reg = <0x1f000000 0x1000>;
			#clock-cells = <1>;
			status = "disabled";
		};
	};

	/*
	 * Trips stay below the stock ones (stock: critical 119 C, the same
	 * as the LVTS hardware reset): passive 85 C throttles the cluster,
	 * critical 110 C powers off in an orderly way before the hardware
	 * reset. Little sensor N is taken as CPU N (stock: little-coreN).
	 */
	thermal_zones: thermal-zones {
		cpu4-0-thermal {
			polling-delay = <1000>;
			polling-delay-passive = <250>;
			thermal-sensors = <&lvts_mcu MT6878_MCU_BIG_CPU4_0>;

			trips {
				cpu4_0_alert: trip-alert {
					temperature = <85000>;
					hysteresis = <2000>;
					type = "passive";
				};

				cpu4_0_crit: trip-crit {
					temperature = <110000>;
					hysteresis = <0>;
					type = "critical";
				};
			};

			cooling-maps {
				map0 {
					trip = <&cpu4_0_alert>;
					cooling-device = <&cpu4 THERMAL_NO_LIMIT THERMAL_NO_LIMIT>,
							 <&cpu5 THERMAL_NO_LIMIT THERMAL_NO_LIMIT>,
							 <&cpu6 THERMAL_NO_LIMIT THERMAL_NO_LIMIT>,
							 <&cpu7 THERMAL_NO_LIMIT THERMAL_NO_LIMIT>;
				};
			};
		};

		cpu4-1-thermal {
			polling-delay = <1000>;
			polling-delay-passive = <250>;
			thermal-sensors = <&lvts_mcu MT6878_MCU_BIG_CPU4_1>;

			trips {
				cpu4_1_alert: trip-alert {
					temperature = <85000>;
					hysteresis = <2000>;
					type = "passive";
				};

				cpu4_1_crit: trip-crit {
					temperature = <110000>;
					hysteresis = <0>;
					type = "critical";
				};
			};

			cooling-maps {
				map0 {
					trip = <&cpu4_1_alert>;
					cooling-device = <&cpu4 THERMAL_NO_LIMIT THERMAL_NO_LIMIT>,
							 <&cpu5 THERMAL_NO_LIMIT THERMAL_NO_LIMIT>,
							 <&cpu6 THERMAL_NO_LIMIT THERMAL_NO_LIMIT>,
							 <&cpu7 THERMAL_NO_LIMIT THERMAL_NO_LIMIT>;
				};
			};
		};

		cpu5-0-thermal {
			polling-delay = <1000>;
			polling-delay-passive = <250>;
			thermal-sensors = <&lvts_mcu MT6878_MCU_BIG_CPU5_0>;

			trips {
				cpu5_0_alert: trip-alert {
					temperature = <85000>;
					hysteresis = <2000>;
					type = "passive";
				};

				cpu5_0_crit: trip-crit {
					temperature = <110000>;
					hysteresis = <0>;
					type = "critical";
				};
			};

			cooling-maps {
				map0 {
					trip = <&cpu5_0_alert>;
					cooling-device = <&cpu4 THERMAL_NO_LIMIT THERMAL_NO_LIMIT>,
							 <&cpu5 THERMAL_NO_LIMIT THERMAL_NO_LIMIT>,
							 <&cpu6 THERMAL_NO_LIMIT THERMAL_NO_LIMIT>,
							 <&cpu7 THERMAL_NO_LIMIT THERMAL_NO_LIMIT>;
				};
			};
		};

		cpu5-1-thermal {
			polling-delay = <1000>;
			polling-delay-passive = <250>;
			thermal-sensors = <&lvts_mcu MT6878_MCU_BIG_CPU5_1>;

			trips {
				cpu5_1_alert: trip-alert {
					temperature = <85000>;
					hysteresis = <2000>;
					type = "passive";
				};

				cpu5_1_crit: trip-crit {
					temperature = <110000>;
					hysteresis = <0>;
					type = "critical";
				};
			};

			cooling-maps {
				map0 {
					trip = <&cpu5_1_alert>;
					cooling-device = <&cpu4 THERMAL_NO_LIMIT THERMAL_NO_LIMIT>,
							 <&cpu5 THERMAL_NO_LIMIT THERMAL_NO_LIMIT>,
							 <&cpu6 THERMAL_NO_LIMIT THERMAL_NO_LIMIT>,
							 <&cpu7 THERMAL_NO_LIMIT THERMAL_NO_LIMIT>;
				};
			};
		};

		cpu6-0-thermal {
			polling-delay = <1000>;
			polling-delay-passive = <250>;
			thermal-sensors = <&lvts_mcu MT6878_MCU_BIG_CPU6_0>;

			trips {
				cpu6_0_alert: trip-alert {
					temperature = <85000>;
					hysteresis = <2000>;
					type = "passive";
				};

				cpu6_0_crit: trip-crit {
					temperature = <110000>;
					hysteresis = <0>;
					type = "critical";
				};
			};

			cooling-maps {
				map0 {
					trip = <&cpu6_0_alert>;
					cooling-device = <&cpu4 THERMAL_NO_LIMIT THERMAL_NO_LIMIT>,
							 <&cpu5 THERMAL_NO_LIMIT THERMAL_NO_LIMIT>,
							 <&cpu6 THERMAL_NO_LIMIT THERMAL_NO_LIMIT>,
							 <&cpu7 THERMAL_NO_LIMIT THERMAL_NO_LIMIT>;
				};
			};
		};

		cpu6-1-thermal {
			polling-delay = <1000>;
			polling-delay-passive = <250>;
			thermal-sensors = <&lvts_mcu MT6878_MCU_BIG_CPU6_1>;

			trips {
				cpu6_1_alert: trip-alert {
					temperature = <85000>;
					hysteresis = <2000>;
					type = "passive";
				};

				cpu6_1_crit: trip-crit {
					temperature = <110000>;
					hysteresis = <0>;
					type = "critical";
				};
			};

			cooling-maps {
				map0 {
					trip = <&cpu6_1_alert>;
					cooling-device = <&cpu4 THERMAL_NO_LIMIT THERMAL_NO_LIMIT>,
							 <&cpu5 THERMAL_NO_LIMIT THERMAL_NO_LIMIT>,
							 <&cpu6 THERMAL_NO_LIMIT THERMAL_NO_LIMIT>,
							 <&cpu7 THERMAL_NO_LIMIT THERMAL_NO_LIMIT>;
				};
			};
		};

		cpu7-0-thermal {
			polling-delay = <1000>;
			polling-delay-passive = <250>;
			thermal-sensors = <&lvts_mcu MT6878_MCU_BIG_CPU7_0>;

			trips {
				cpu7_0_alert: trip-alert {
					temperature = <85000>;
					hysteresis = <2000>;
					type = "passive";
				};

				cpu7_0_crit: trip-crit {
					temperature = <110000>;
					hysteresis = <0>;
					type = "critical";
				};
			};

			cooling-maps {
				map0 {
					trip = <&cpu7_0_alert>;
					cooling-device = <&cpu4 THERMAL_NO_LIMIT THERMAL_NO_LIMIT>,
							 <&cpu5 THERMAL_NO_LIMIT THERMAL_NO_LIMIT>,
							 <&cpu6 THERMAL_NO_LIMIT THERMAL_NO_LIMIT>,
							 <&cpu7 THERMAL_NO_LIMIT THERMAL_NO_LIMIT>;
				};
			};
		};

		cpu7-1-thermal {
			polling-delay = <1000>;
			polling-delay-passive = <250>;
			thermal-sensors = <&lvts_mcu MT6878_MCU_BIG_CPU7_1>;

			trips {
				cpu7_1_alert: trip-alert {
					temperature = <85000>;
					hysteresis = <2000>;
					type = "passive";
				};

				cpu7_1_crit: trip-crit {
					temperature = <110000>;
					hysteresis = <0>;
					type = "critical";
				};
			};

			cooling-maps {
				map0 {
					trip = <&cpu7_1_alert>;
					cooling-device = <&cpu4 THERMAL_NO_LIMIT THERMAL_NO_LIMIT>,
							 <&cpu5 THERMAL_NO_LIMIT THERMAL_NO_LIMIT>,
							 <&cpu6 THERMAL_NO_LIMIT THERMAL_NO_LIMIT>,
							 <&cpu7 THERMAL_NO_LIMIT THERMAL_NO_LIMIT>;
				};
			};
		};

		cpu0-thermal {
			polling-delay = <1000>;
			polling-delay-passive = <250>;
			thermal-sensors = <&lvts_mcu MT6878_MCU_LITTLE_CPU0>;

			trips {
				cpu0_alert: trip-alert {
					temperature = <85000>;
					hysteresis = <2000>;
					type = "passive";
				};

				cpu0_crit: trip-crit {
					temperature = <110000>;
					hysteresis = <0>;
					type = "critical";
				};
			};

			cooling-maps {
				map0 {
					trip = <&cpu0_alert>;
					cooling-device = <&cpu0 THERMAL_NO_LIMIT THERMAL_NO_LIMIT>,
							 <&cpu1 THERMAL_NO_LIMIT THERMAL_NO_LIMIT>,
							 <&cpu2 THERMAL_NO_LIMIT THERMAL_NO_LIMIT>,
							 <&cpu3 THERMAL_NO_LIMIT THERMAL_NO_LIMIT>;
				};
			};
		};

		cpu1-thermal {
			polling-delay = <1000>;
			polling-delay-passive = <250>;
			thermal-sensors = <&lvts_mcu MT6878_MCU_LITTLE_CPU1>;

			trips {
				cpu1_alert: trip-alert {
					temperature = <85000>;
					hysteresis = <2000>;
					type = "passive";
				};

				cpu1_crit: trip-crit {
					temperature = <110000>;
					hysteresis = <0>;
					type = "critical";
				};
			};

			cooling-maps {
				map0 {
					trip = <&cpu1_alert>;
					cooling-device = <&cpu0 THERMAL_NO_LIMIT THERMAL_NO_LIMIT>,
							 <&cpu1 THERMAL_NO_LIMIT THERMAL_NO_LIMIT>,
							 <&cpu2 THERMAL_NO_LIMIT THERMAL_NO_LIMIT>,
							 <&cpu3 THERMAL_NO_LIMIT THERMAL_NO_LIMIT>;
				};
			};
		};

		cpu2-thermal {
			polling-delay = <1000>;
			polling-delay-passive = <250>;
			thermal-sensors = <&lvts_mcu MT6878_MCU_LITTLE_CPU2>;

			trips {
				cpu2_alert: trip-alert {
					temperature = <85000>;
					hysteresis = <2000>;
					type = "passive";
				};

				cpu2_crit: trip-crit {
					temperature = <110000>;
					hysteresis = <0>;
					type = "critical";
				};
			};

			cooling-maps {
				map0 {
					trip = <&cpu2_alert>;
					cooling-device = <&cpu0 THERMAL_NO_LIMIT THERMAL_NO_LIMIT>,
							 <&cpu1 THERMAL_NO_LIMIT THERMAL_NO_LIMIT>,
							 <&cpu2 THERMAL_NO_LIMIT THERMAL_NO_LIMIT>,
							 <&cpu3 THERMAL_NO_LIMIT THERMAL_NO_LIMIT>;
				};
			};
		};

		cpu3-thermal {
			polling-delay = <1000>;
			polling-delay-passive = <250>;
			thermal-sensors = <&lvts_mcu MT6878_MCU_LITTLE_CPU3>;

			trips {
				cpu3_alert: trip-alert {
					temperature = <85000>;
					hysteresis = <2000>;
					type = "passive";
				};

				cpu3_crit: trip-crit {
					temperature = <110000>;
					hysteresis = <0>;
					type = "critical";
				};
			};

			cooling-maps {
				map0 {
					trip = <&cpu3_alert>;
					cooling-device = <&cpu0 THERMAL_NO_LIMIT THERMAL_NO_LIMIT>,
							 <&cpu1 THERMAL_NO_LIMIT THERMAL_NO_LIMIT>,
							 <&cpu2 THERMAL_NO_LIMIT THERMAL_NO_LIMIT>,
							 <&cpu3 THERMAL_NO_LIMIT THERMAL_NO_LIMIT>;
				};
			};
		};

		dsu0-thermal {
			polling-delay = <1000>;
			polling-delay-passive = <250>;
			thermal-sensors = <&lvts_mcu MT6878_MCU_DSU0>;

			trips {
				dsu0_crit: trip-crit {
					temperature = <110000>;
					hysteresis = <0>;
					type = "critical";
				};
			};
		};

		dsu1-thermal {
			polling-delay = <1000>;
			polling-delay-passive = <250>;
			thermal-sensors = <&lvts_mcu MT6878_MCU_DSU1>;

			trips {
				dsu1_crit: trip-crit {
					temperature = <110000>;
					hysteresis = <0>;
					type = "critical";
				};
			};
		};

		soc-top0-thermal {
			polling-delay = <1000>;
			polling-delay-passive = <250>;
			thermal-sensors = <&lvts_ap MT6878_AP_SOC_TOP0>;

			trips {
				soc_top0_crit: trip-crit {
					temperature = <110000>;
					hysteresis = <0>;
					type = "critical";
				};
			};
		};

		soc-top1-thermal {
			polling-delay = <1000>;
			polling-delay-passive = <250>;
			thermal-sensors = <&lvts_ap MT6878_AP_SOC_TOP1>;

			trips {
				soc_top1_crit: trip-crit {
					temperature = <110000>;
					hysteresis = <0>;
					type = "critical";
				};
			};
		};

		apu-thermal {
			polling-delay = <1000>;
			polling-delay-passive = <250>;
			thermal-sensors = <&lvts_ap MT6878_AP_APU>;

			trips {
				apu_crit: trip-crit {
					temperature = <110000>;
					hysteresis = <0>;
					type = "critical";
				};
			};
		};

		soc-bot0-thermal {
			polling-delay = <1000>;
			polling-delay-passive = <250>;
			thermal-sensors = <&lvts_ap MT6878_AP_SOC_BOT0>;

			trips {
				soc_bot0_crit: trip-crit {
					temperature = <110000>;
					hysteresis = <0>;
					type = "critical";
				};
			};
		};

		soc-bot1-thermal {
			polling-delay = <1000>;
			polling-delay-passive = <250>;
			thermal-sensors = <&lvts_ap MT6878_AP_SOC_BOT1>;

			trips {
				soc_bot1_crit: trip-crit {
					temperature = <110000>;
					hysteresis = <0>;
					type = "critical";
				};
			};
		};

		md0-thermal {
			polling-delay = <1000>;
			polling-delay-passive = <250>;
			thermal-sensors = <&lvts_ap MT6878_AP_MD0>;

			trips {
				md0_crit: trip-crit {
					temperature = <110000>;
					hysteresis = <0>;
					type = "critical";
				};
			};
		};

		md1-thermal {
			polling-delay = <1000>;
			polling-delay-passive = <250>;
			thermal-sensors = <&lvts_ap MT6878_AP_MD1>;

			trips {
				md1_crit: trip-crit {
					temperature = <110000>;
					hysteresis = <0>;
					type = "critical";
				};
			};
		};

		md2-thermal {
			polling-delay = <1000>;
			polling-delay-passive = <250>;
			thermal-sensors = <&lvts_ap MT6878_AP_MD2>;

			trips {
				md2_crit: trip-crit {
					temperature = <110000>;
					hysteresis = <0>;
					type = "critical";
				};
			};
		};

		md3-thermal {
			polling-delay = <1000>;
			polling-delay-passive = <250>;
			thermal-sensors = <&lvts_ap MT6878_AP_MD3>;

			trips {
				md3_crit: trip-crit {
					temperature = <110000>;
					hysteresis = <0>;
					type = "critical";
				};
			};
		};
	};

	timer {
		compatible = "arm,armv8-timer";
		interrupt-parent = <&gic>;
		interrupts = <GIC_PPI 13 IRQ_TYPE_LEVEL_LOW 0>,
			     <GIC_PPI 14 IRQ_TYPE_LEVEL_LOW 0>,
			     <GIC_PPI 11 IRQ_TYPE_LEVEL_LOW 0>,
			     <GIC_PPI 10 IRQ_TYPE_LEVEL_LOW 0>;
	};

	reserved-memory {
		#address-cells = <2>;
		#size-cells = <2>;
		ranges;

		mblock-47-sspm_ap-shared {
			reg = <0x00 0x7f970000 0x00 0x110000>;
			no-map;
			compatible = "mediatek,sspm_ap-shared";
		};

		mblock-46-me_GPUEB_SHARED {
			reg = <0x00 0x7fe70000 0x00 0x180000>;
			no-map;
			compatible = "mediatek,me_GPUEB_SHARED";
		};

		mblock-45-adsp_shared_reserved {
			reg = <0x00 0x9e000000 0x00 0xb40000>;
			no-map;
			compatible = "mediatek,adsp_shared_reserved";
		};

		mblock-44-debug_met_res-ram {
			reg = <0x00 0x9f3ff000 0x00 0xc00000>;
			no-map;
			compatible = "mediatek,debug_met_res-ram";
		};

		mblock-43-consys_scp_emi-reserved {
			reg = <0x00 0x87f00000 0x00 0x20000>;
			no-map;
			compatible = "mediatek,consys_scp_emi-reserved";
		};

		mblock-42-shared-dma-pool_wifi-reserve-memory_dma {
			phandle = <0x312>;
			reg = <0x00 0x86b00000 0x00 0x1400000>;
			no-map;
			compatible = "shared-dma-pool";
		};

		mblock-41-consys_emi_reserved {
			reg = <0x00 0x85e00000 0x00 0xd00000>;
			no-map;
			compatible = "mediatek,consys_emi_reserved";
		};

		mblock-40-me_GPUmputab_PMA {
			reg = <0x00 0x7e800000 0x00 0x600000>;
			no-map;
			compatible = "mediatek,me_GPUmputab_PMA";
		};

		mblock-39-me_vcp_reserved {
			reg = <0x00 0xbf500000 0x00 0x800000>;
			no-map;
			compatible = "mediatek,me_vcp_reserved";
		};

		mblock-38-md_mem_usage {
			reg = <0x00 0xed780000 0x00 0x880000>;
			no-map;
			compatible = "mediatek,md_mem_usage";
		};

		mblock-37-md_mem_usage {
			reg = <0x00 0xd4000000 0x00 0x6d50000>;
			no-map;
			compatible = "mediatek,md_mem_usage";
		};

		mblock-36-md_mem_usage {
			reg = <0x00 0xd3500000 0x00 0x250000>;
			no-map;
			compatible = "mediatek,md_mem_usage";
		};

		mblock-35-ap_md_c_smem {
			reg = <0x00 0x88000000 0x00 0x2560000>;
			no-map;
			compatible = "mediatek,ap_md_c_smem";
		};

		mblock-34-ap_md_nc_smem {
			reg = <0x00 0x8c000000 0x00 0x130000>;
			no-map;
			compatible = "mediatek,ap_md_nc_smem";
		};

		mblock-33-md_mem_usage {
			reg = <0x00 0xd0000000 0x00 0x3410000>;
			no-map;
			compatible = "mediatek,md_mem_usage";
		};

		mblock-32-ccci_tag_mem {
			reg = <0x00 0xbfdf0000 0x00 0x10000>;
			no-map;
			compatible = "mediatek,ccci_tag_mem";
		};

		mblock-31-apu_sapu_apurvgzctrlshm {
			reg = <0x00 0x8f600000 0x00 0x100000>;
			no-map;
			compatible = "mediatek,apu_sapu_apurvgzctrlshm";
		};

		mblock-30-apu_apusys-rv_aee-coredump {
			reg = <0x00 0x8f7a0000 0x00 0x260000>;
			no-map;
			compatible = "mediatek,apu_apusys-rv_aee-coredump";
		};

		mblock-29-mm_ccu_reserved {
			reg = <0x00 0x80000000 0x00 0x100000>;
			no-map;
			compatible = "mediatek,mm_ccu_reserved";
		};

		mblock-28-reserve-memory-scp_share {
			reg = <0x00 0x8e000000 0x00 0x11c8000>;
			no-map;
			compatible = "mediatek,reserve-memory-scp_share";
		};

		mblock-27-SCP-reserved {
			reg = <0x00 0xb8000000 0x00 0x2300000>;
			no-map;
			compatible = "mediatek,SCP-reserved";
		};

		mblock-26-apu_apusys-rv_secure {
			reg = <0x00 0x8fa00000 0x00 0x600000>;
			no-map;
			compatible = "mediatek,apu_apusys-rv_secure";
		};

		mblock-25-platform-debug_dfdsoc_dump {
			reg = <0x00 0xfdc00000 0x00 0x200000>;
			no-map;
			compatible = "mediatek,platform-debug_dfdsoc_dump";
		};

		mblock-24-tee-reserved {
			reg = <0x00 0x70000000 0x00 0x6c00000>;
			no-map;
			compatible = "mediatek,tee-reserved";
		};

		mblock-23-tee-secmem {
			reg = <0x00 0x7f000000 0x00 0x900000>;
			no-map;
			compatible = "mediatek,tee-secmem";
		};

		mblock-22-MCUPM-reserved {
			reg = <0x00 0x7fa80000 0x00 0x100000>;
			no-map;
			compatible = "mediatek,MCUPM-reserved";
		};

		mblock-21-SSPM-reserved {
			reg = <0x00 0x7fb80000 0x00 0x280000>;
			no-map;
			compatible = "mediatek,SSPM-reserved";
		};

		mblock-20-gz-log {
			reg = <0x02 0x3de00000 0x00 0x41000>;
			compatible = "mediatek,gz-log";
		};

		mblock-19-unmap2 {
			reg = <0x02 0x3e000000 0x00 0x200000>;
			no-map;
			compatible = "mediatek,unmap2";
		};

		mblock-18-platform_mtksmmu_protpgd {
			reg = <0x00 0x7b800000 0x00 0x2800000>;
			no-map;
			compatible = "mediatek,platform_mtksmmu_protpgd";
		};

		mblock-17-gz {
			reg = <0x02 0x3e400000 0x00 0x1a00000>;
			no-map;
			compatible = "mediatek,gz";
		};

		mblock-16-me_cmdq_reserved {
			reg = <0x02 0x3fe00000 0x00 0x100000>;
			no-map;
			compatible = "mediatek,me_cmdq_reserved";
		};

		mblock-15-framebuffer {
			reg = <0x00 0xfe0d0000 0x00 0x1f2f000>;
			compatible = "mediatek,framebuffer";
			no-map;
		};

		mblock-14-me_gpu_reserved {
			reg = <0x00 0x7ee00000 0x00 0x200000>;
			no-map;
			compatible = "mediatek,me_gpu_reserved";
		};

		mblock-13-security_dice_common {
			reg = <0x00 0x6fffe000 0x00 0x1000>;
			no-map;
			compatible = "mediatek,security_dice_common";
		};

		mblock-12-atf-log-reserved {
			reg = <0x00 0xbfe00000 0x00 0x200000>;
			no-map;
			compatible = "mediatek,atf-log-reserved";
		};

		mblock-11-log_store {
			reg = <0x02 0x3ffbf000 0x00 0x40000>;
			compatible = "mediatek,log_store";
		};

		mblock-10-emi_mbist_buf {
			reg = <0x00 0x7ffff000 0x00 0x1000>;
			no-map;
			compatible = "mediatek,emi_mbist_buf";
		};

		mblock-9-dramc-rk1 {
			reg = <0x02 0x3ffff000 0x00 0x1000>;
			no-map;
			compatible = "mediatek,dramc-rk1";
		};

		mblock-8-dramc-rk0 {
			reg = <0x01 0x3ffff000 0x00 0x1000>;
			no-map;
			compatible = "mediatek,dramc-rk0";
		};

		mblock-7-platform-debug_dfdmcu_dump {
			reg = <0x00 0xfd000000 0x00 0x100000>;
			no-map;
			compatible = "mediatek,platform-debug_dfdmcu_dump";
		};

		mblock-6-crypto_hw {
			reg = <0x00 0x48401000 0x00 0x1000>;
			no-map;
			compatible = "mediatek,crypto_hw";
		};

		mblock-5-aee_lk {
			reg = <0x00 0x7e000000 0x00 0x800000>;
			compatible = "mediatek,aee_lk";
		};

		mblock-4-BL31-reserved {
			reg = <0x00 0x48800000 0x00 0x200000>;
			no-map;
			compatible = "mediatek,BL31-reserved";
		};

		mblock-3-minirdump {
			reg = <0x00 0x48170000 0x00 0x10000>;
			no-map;
			compatible = "mediatek,minirdump";
		};

		mblock-2-pstore {
			reg = <0x00 0x48090000 0x00 0xe0000>;
			no-map;
			compatible = "mediatek,pstore";
		};

		mblock-1-aee_debug_kinfo {
			phandle = <0x311>;
			reg = <0x00 0x48080000 0x00 0x10000>;
			no-map;
			compatible = "mediatek,aee_debug_kinfo";
		};

		ccci-dpmaif-cache-memory {
			compatible = "mediatek,dpmaif-resv-cache-mem";
			size = <0x00 0x190000>;
			alignment = <0x00 0x1000>;
			alloc-ranges = <0x00 0x40000000 0x00 0xf0000000>;
			phandle = <0x14b>;
		};

		ccci-dpmaif-nocache-memory {
			compatible = "mediatek,dpmaif-resv-nocache-mem";
			no-map;
			size = <0x00 0x50000>;
			alignment = <0x00 0x1000>;
			alloc-ranges = <0x00 0x40000000 0x00 0xf0000000>;
			phandle = <0x14c>;
		};

		ssmr-reserved-cma-memory {
			alloc-ranges = <0x00 0x80000000 0x00 0xc0000000>;
			compatible = "shared-dma-pool";
			reusable;
			size = <0x00 0xd000000>;
			alignment = <0x00 0x1000000>;
			phandle = <0x20>;
		};
	};
};
